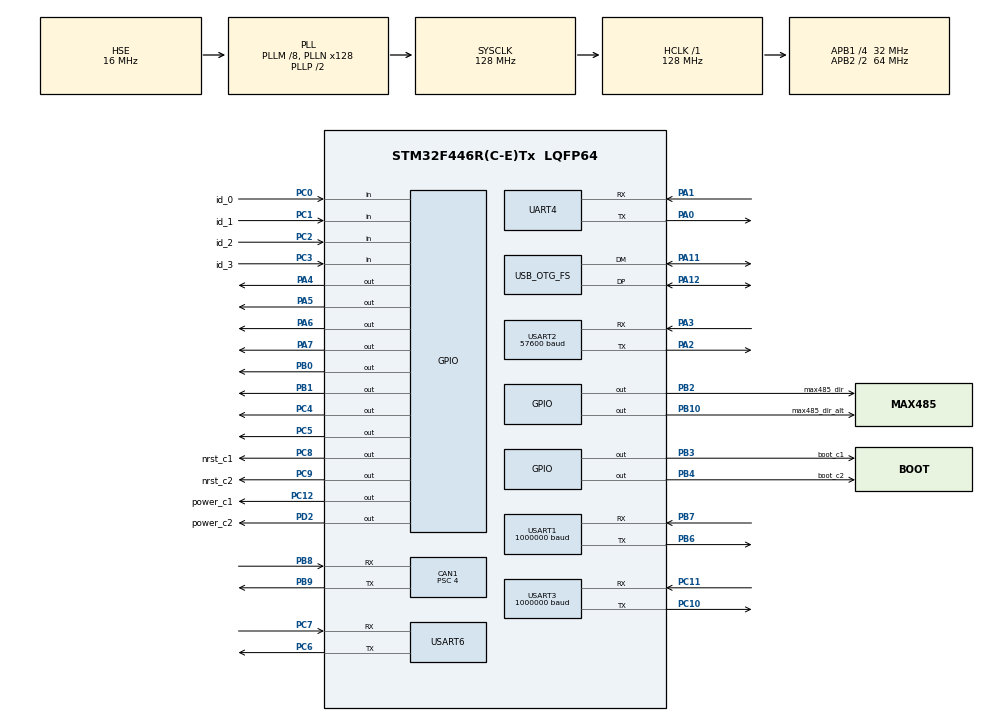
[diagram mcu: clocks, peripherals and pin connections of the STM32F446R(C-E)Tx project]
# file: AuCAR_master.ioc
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CAN1.BS1=CAN_BS1_6TQ
CAN1.CalculateTimeQuantum=125.0
CAN1.NART=ENABLE
CAN1.Prescaler=4
Dma.Request0=USART2_RX
Dma.Request1=USART2_TX
Dma.Request2=USART1_RX
Dma.Request3=USART1_TX
Dma.Request4=USART3_RX
Dma.Request5=USART3_TX
Dma.USART1_RX.2.Direction=DMA_PERIPH_TO_MEMORY
Dma.USART1_RX.2.FIFOMode=DMA_FIFOMODE_DISABLE
Dma.USART1_RX.2.Instance=DMA2_Stream2
Dma.USART1_RX.2.MemDataAlignment=DMA_MDATAALIGN_BYTE
Dma.USART1_RX.2.MemInc=DMA_MINC_ENABLE
Dma.USART1_RX.2.Mode=DMA_CIRCULAR
Dma.USART1_RX.2.PeriphDataAlignment=DMA_PDATAALIGN_BYTE
Dma.USART1_RX.2.PeriphInc=DMA_PINC_DISABLE
Dma.USART1_RX.2.Priority=DMA_PRIORITY_LOW
Dma.USART1_TX.3.Direction=DMA_MEMORY_TO_PERIPH
Dma.USART1_TX.3.FIFOMode=DMA_FIFOMODE_DISABLE
Dma.USART1_TX.3.Instance=DMA2_Stream7
Dma.USART1_TX.3.MemDataAlignment=DMA_MDATAALIGN_BYTE
Dma.USART1_TX.3.MemInc=DMA_MINC_ENABLE
Dma.USART1_TX.3.Mode=DMA_NORMAL
Dma.USART1_TX.3.PeriphDataAlignment=DMA_PDATAALIGN_BYTE
Dma.USART1_TX.3.PeriphInc=DMA_PINC_DISABLE
Dma.USART1_TX.3.Priority=DMA_PRIORITY_LOW
Dma.USART2_RX.0.Direction=DMA_PERIPH_TO_MEMORY
Dma.USART2_RX.0.FIFOMode=DMA_FIFOMODE_DISABLE
Dma.USART2_RX.0.Instance=DMA1_Stream5
Dma.USART2_RX.0.MemDataAlignment=DMA_MDATAALIGN_BYTE
Dma.USART2_RX.0.MemInc=DMA_MINC_ENABLE
Dma.USART2_RX.0.Mode=DMA_CIRCULAR
Dma.USART2_RX.0.PeriphDataAlignment=DMA_PDATAALIGN_BYTE
Dma.USART2_RX.0.PeriphInc=DMA_PINC_DISABLE
Dma.USART2_RX.0.Priority=DMA_PRIORITY_LOW
Dma.USART2_TX.1.Direction=DMA_MEMORY_TO_PERIPH
Dma.USART2_TX.1.FIFOMode=DMA_FIFOMODE_DISABLE
Dma.USART2_TX.1.Instance=DMA1_Stream6
Dma.USART2_TX.1.MemDataAlignment=DMA_MDATAALIGN_BYTE
Dma.USART2_TX.1.MemInc=DMA_MINC_ENABLE
Dma.USART2_TX.1.Mode=DMA_NORMAL
Dma.USART2_TX.1.PeriphDataAlignment=DMA_PDATAALIGN_BYTE
Dma.USART2_TX.1.PeriphInc=DMA_PINC_DISABLE
Dma.USART2_TX.1.Priority=DMA_PRIORITY_LOW
Dma.USART3_RX.4.Direction=DMA_PERIPH_TO_MEMORY
Dma.USART3_RX.4.FIFOMode=DMA_FIFOMODE_DISABLE
Dma.USART3_RX.4.Instance=DMA1_Stream1
Dma.USART3_RX.4.MemDataAlignment=DMA_MDATAALIGN_BYTE
Dma.USART3_RX.4.MemInc=DMA_MINC_ENABLE
Dma.USART3_RX.4.Mode=DMA_CIRCULAR
Dma.USART3_RX.4.PeriphDataAlignment=DMA_PDATAALIGN_BYTE
Dma.USART3_RX.4.PeriphInc=DMA_PINC_DISABLE
Dma.USART3_RX.4.Priority=DMA_PRIORITY_LOW
Dma.USART3_TX.5.Direction=DMA_MEMORY_TO_PERIPH
Dma.USART3_TX.5.FIFOMode=DMA_FIFOMODE_DISABLE
Dma.USART3_TX.5.Instance=DMA1_Stream3
Dma.USART3_TX.5.MemDataAlignment=DMA_MDATAALIGN_BYTE
Dma.USART3_TX.5.MemInc=DMA_MINC_ENABLE
Dma.USART3_TX.5.Mode=DMA_NORMAL
Dma.USART3_TX.5.PeriphDataAlignment=DMA_PDATAALIGN_BYTE
Dma.USART3_TX.5.PeriphInc=DMA_PINC_DISABLE
Dma.USART3_TX.5.Priority=DMA_PRIORITY_LOW
Mcu.Family=STM32F4
Mcu.Name=STM32F446R(C-E)Tx
Mcu.Package=LQFP64
NVIC.CAN1_RX0_IRQn=true\:0\:0\:false\:false\:true\:true\:true
NVIC.CAN1_RX1_IRQn=true\:0\:0\:false\:false\:true\:true\:true
NVIC.CAN1_SCE_IRQn=true\:0\:0\:false\:false\:true\:true\:true
NVIC.CAN1_TX_IRQn=true\:0\:0\:false\:false\:true\:true\:true
NVIC.DMA1_Stream1_IRQn=true\:0\:0\:false\:false\:true\:false\:true
NVIC.DMA1_Stream3_IRQn=true\:0\:0\:false\:false\:true\:false\:true
NVIC.DMA1_Stream5_IRQn=true\:0\:0\:false\:false\:true\:false\:true
NVIC.DMA1_Stream6_IRQn=true\:0\:0\:false\:false\:true\:false\:true
NVIC.DMA2_Stream2_IRQn=true\:0\:0\:false\:false\:true\:false\:true
NVIC.DMA2_Stream7_IRQn=true\:0\:0\:false\:false\:true\:false\:true
NVIC.OTG_FS_IRQn=true\:0\:0\:false\:false\:true\:true\:true
NVIC.PriorityGroup=NVIC_PRIORITYGROUP_4
NVIC.RCC_IRQn=true\:0\:0\:false\:false\:true\:true\:false
NVIC.TIM6_DAC_IRQn=true\:0\:0\:false\:false\:true\:true\:true
NVIC.TIM7_IRQn=true\:0\:0\:false\:false\:true\:true\:true
NVIC.UART4_IRQn=true\:0\:0\:false\:false\:true\:true\:true
NVIC.USART1_IRQn=true\:0\:0\:false\:false\:true\:true\:true
NVIC.USART2_IRQn=true\:0\:0\:false\:false\:true\:true\:true
NVIC.USART3_IRQn=true\:0\:0\:false\:false\:true\:true\:true
NVIC.USART6_IRQn=true\:0\:0\:false\:false\:true\:true\:true
PA0-WKUP.Mode=Asynchronous
PA0-WKUP.Signal=UART4_TX
PA1.Mode=Asynchronous
PA1.Signal=UART4_RX
PA11.Mode=Device_Only
PA11.Signal=USB_OTG_FS_DM
PA12.Mode=Device_Only
PA12.Signal=USB_OTG_FS_DP
PA13.Mode=Serial_Wire
PA13.Signal=SYS_JTMS-SWDIO
PA14.Mode=Serial_Wire
PA14.Signal=SYS_JTCK-SWCLK
PA2.Mode=Asynchronous
PA2.Signal=USART2_TX
PA3.Mode=Asynchronous
PA3.Signal=USART2_RX
PA4.Signal=GPIO_Output
PA5.Signal=GPIO_Output
PA6.Signal=GPIO_Output
PA7.Signal=GPIO_Output
PB0.Signal=GPIO_Output
PB1.Signal=GPIO_Output
PB10.GPIO_Label=max485_dir_alt
PB10.Signal=GPIO_Output
PB2.GPIO_Label=max485_dir
PB2.Signal=GPIO_Output
PB3.GPIO_Label=boot_c1
PB3.Signal=GPIO_Output
PB4.GPIO_Label=boot_c2
PB4.GPIO_PuPd=GPIO_NOPULL
PB4.Signal=GPIO_Output
PB6.Mode=Asynchronous
PB6.Signal=USART1_TX
PB7.Mode=Asynchronous
PB7.Signal=USART1_RX
PB8.Mode=Master
PB8.Signal=CAN1_RX
PB9.Mode=Master
PB9.Signal=CAN1_TX
PC0.GPIO_Label=id_0
PC0.Signal=GPIO_Input
PC1.GPIO_Label=id_1
PC1.Signal=GPIO_Input
PC10.Mode=Asynchronous
PC10.Signal=USART3_TX
PC11.Mode=Asynchronous
PC11.Signal=USART3_RX
PC12.GPIO_Label=power_c1
PC12.GPIO_PuPd=GPIO_NOPULL
PC12.Signal=GPIO_Output
PC2.GPIO_Label=id_2
PC2.Signal=GPIO_Input
PC3.GPIO_Label=id_3
PC3.Signal=GPIO_Input
PC4.GPIO_ModeDefaultOutputPP=GPIO_MODE_OUTPUT_PP
PC4.Signal=GPIO_Output
PC5.Signal=GPIO_Output
PC6.Mode=Asynchronous
PC6.Signal=USART6_TX
PC7.Mode=Asynchronous
PC7.Signal=USART6_RX
PC8.GPIO_Label=nrst_c1
PC8.Signal=GPIO_Output
PC9.GPIO_Label=nrst_c2
PC9.Signal=GPIO_Output
PD2.GPIO_Label=power_c2
PD2.Signal=GPIO_Output
PH0-OSC_IN.Mode=HSE-External-Oscillator
PH0-OSC_IN.Signal=RCC_OSC_IN
PH1-OSC_OUT.Mode=HSE-External-Oscillator
PH1-OSC_OUT.Signal=RCC_OSC_OUT
ProjectManager.HeapSize=0x400
ProjectManager.StackSize=0x800
ProjectManager.TargetToolchain=STM32CubeIDE
RCC.AHBFreq_Value=128000000
RCC.APB1CLKDivider=RCC_HCLK_DIV4
RCC.APB1Freq_Value=32000000
RCC.APB1TimFreq_Value=64000000
RCC.APB2CLKDivider=RCC_HCLK_DIV2
RCC.APB2Freq_Value=64000000
RCC.APB2TimFreq_Value=128000000
RCC.CortexFreq_Value=128000000
RCC.HCLKFreq_Value=128000000
RCC.HSE_VALUE=16000000
RCC.PLLM=8
RCC.PLLN=128
RCC.PLLQ=7
RCC.PLLSAIP=RCC_PLLSAIP_DIV4
RCC.SYSCLKFreq_VALUE=128000000
RCC.SYSCLKSource=RCC_SYSCLKSOURCE_PLLCLK
RCC.USBCLockSelection=RCC_CLK48CLKSOURCE_PLLSAIP
RCC.USBFreq_Value=48000000
RCC.VCOOutputFreq_Value=256000000
TIM2.Period=0xFFFFFFFF
TIM2.Prescaler=64000-1
TIM6.Period=9999
TIM6.Prescaler=6399
TIM7.Period=99
TIM7.Prescaler=6399
UART4.VirtualMode=Asynchronous
USART1.BaudRate=1000000
USART1.VirtualMode=VM_ASYNC
USART2.BaudRate=57600
USART2.VirtualMode=VM_ASYNC
USART3.BaudRate=1000000
USART3.VirtualMode=VM_ASYNC
USART6.VirtualMode=VM_ASYNC
USB_DEVICE.CLASS_NAME_FS=CDC
USB_DEVICE.VirtualMode-CDC_FS=Cdc
USB_DEVICE.VirtualModeFS=Cdc_FS
USB_OTG_FS.VirtualMode=Device_Only
VP_TIM2_VS_ClockSourceINT.Mode=Internal
VP_TIM6_VS_ClockSourceINT.Mode=Enable_Timer
VP_TIM7_VS_ClockSourceINT.Mode=Enable_Timer
VP_USB_DEVICE_VS_USB_DEVICE_CDC_FS.Mode=CDC_FS
board=custom

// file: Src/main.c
/* USER CODE BEGIN Header */
/**
  ******************************************************************************
  * @file           : main.c
  * @brief          : Main program body
  ******************************************************************************
  * @attention
  *
  * <h2><center>&copy; Copyright (c) 2019 STMicroelectronics.
  * All rights reserved.</center></h2>
  *
  * This software component is licensed by ST under BSD 3-Clause license,
  * the "License"; You may not use this file except in compliance with the
  * License. You may obtain a copy of the License at:
  *                        opensource.org/licenses/BSD-3-Clause
  *
  ******************************************************************************
  */
/* USER CODE END Header */

#include "main.h"
#include "can.h"
#include "dma.h"
#include "tim.h"
#include "usart.h"
#include "usb_device.h"
#include "gpio.h"

/* USER CODE BEGIN Includes */
#include "master_main.h"
/* USER CODE END Includes */

/* USER CODE BEGIN PV */
extern uint8_t UserRxBufferFS[APP_RX_DATA_SIZE];
extern uint8_t UserTxBufferFS[APP_TX_DATA_SIZE];
/* USER CODE END PV */

void SystemClock_Config(void);

/* USER CODE BEGIN 0 */
int __io_putchar(int ch)
{
	//__usart2.write((uint8_t*)ch, 1);
	__printf__io__putchar(ch);
	return ch;
}

/* USER CODE END 0 */

int main(void)
{

  /* MCU Configuration--------------------------------------------------------*/

  /* Reset of all peripherals, Initializes the Flash interface and the Systick. */
   HAL_Init();

  /* Configure the system clock */
  SystemClock_Config();

  /* Initialize all configured peripherals */
  MX_GPIO_Init();
  MX_DMA_Init();
  MX_CAN1_Init();
  MX_UART4_Init();
  MX_USART1_UART_Init();
  MX_USART2_UART_Init();
  MX_USART3_UART_Init();
  MX_USART6_UART_Init();
  MX_TIM6_Init();
  MX_TIM7_Init();
  MX_USB_DEVICE_Init();
  MX_TIM2_Init();
  /* USER CODE BEGIN 2 */

  init();

  /* USER CODE END 2 */

  /* Infinite loop */
  while (1)
  {

    /* USER CODE BEGIN 3 */
	  run();

  }
  /* USER CODE END 3 */
}

void SystemClock_Config(void)
{
  RCC_OscInitTypeDef RCC_OscInitStruct = {0};
  RCC_ClkInitTypeDef RCC_ClkInitStruct = {0};
  RCC_PeriphCLKInitTypeDef PeriphClkInitStruct = {0};

  /** Configure the main internal regulator output voltage
  */
  __HAL_RCC_PWR_CLK_ENABLE();
  __HAL_PWR_VOLTAGESCALING_CONFIG(PWR_REGULATOR_VOLTAGE_SCALE2);
  /** Initializes the CPU, AHB and APB busses clocks
  */
  RCC_OscInitStruct.OscillatorType = RCC_OSCILLATORTYPE_HSE;
  RCC_OscInitStruct.HSEState = RCC_HSE_ON;
  RCC_OscInitStruct.PLL.PLLState = RCC_PLL_ON;
  RCC_OscInitStruct.PLL.PLLSource = RCC_PLLSOURCE_HSE;
  RCC_OscInitStruct.PLL.PLLM = 8;
  RCC_OscInitStruct.PLL.PLLN = 128;
  RCC_OscInitStruct.PLL.PLLP = RCC_PLLP_DIV2;
  RCC_OscInitStruct.PLL.PLLQ = 7;
  RCC_OscInitStruct.PLL.PLLR = 2;
  if (HAL_RCC_OscConfig(&RCC_OscInitStruct) != HAL_OK)
  {
    Error_Handler();
  }
  /** Initializes the CPU, AHB and APB busses clocks
  */
  RCC_ClkInitStruct.ClockType = RCC_CLOCKTYPE_HCLK|RCC_CLOCKTYPE_SYSCLK
                              |RCC_CLOCKTYPE_PCLK1|RCC_CLOCKTYPE_PCLK2;
  RCC_ClkInitStruct.SYSCLKSource = RCC_SYSCLKSOURCE_PLLCLK;
  RCC_ClkInitStruct.AHBCLKDivider = RCC_SYSCLK_DIV1;
  RCC_ClkInitStruct.APB1CLKDivider = RCC_HCLK_DIV4;
  RCC_ClkInitStruct.APB2CLKDivider = RCC_HCLK_DIV2;

  if (HAL_RCC_ClockConfig(&RCC_ClkInitStruct, FLASH_LATENCY_4) != HAL_OK)
  {
    Error_Handler();
  }
  PeriphClkInitStruct.PeriphClockSelection = RCC_PERIPHCLK_CLK48;
  PeriphClkInitStruct.PLLSAI.PLLSAIM = 16;
  PeriphClkInitStruct.PLLSAI.PLLSAIN = 192;
  PeriphClkInitStruct.PLLSAI.PLLSAIQ = 2;
  PeriphClkInitStruct.PLLSAI.PLLSAIP = RCC_PLLSAIP_DIV4;
  PeriphClkInitStruct.PLLSAIDivQ = 1;
  PeriphClkInitStruct.Clk48ClockSelection = RCC_CLK48CLKSOURCE_PLLSAIP;
  if (HAL_RCCEx_PeriphCLKConfig(&PeriphClkInitStruct) != HAL_OK)
  {
    Error_Handler();
  }
}

void Error_Handler(void)
{
}

/************************ (C) COPYRIGHT STMicroelectronics *****END OF FILE****/
